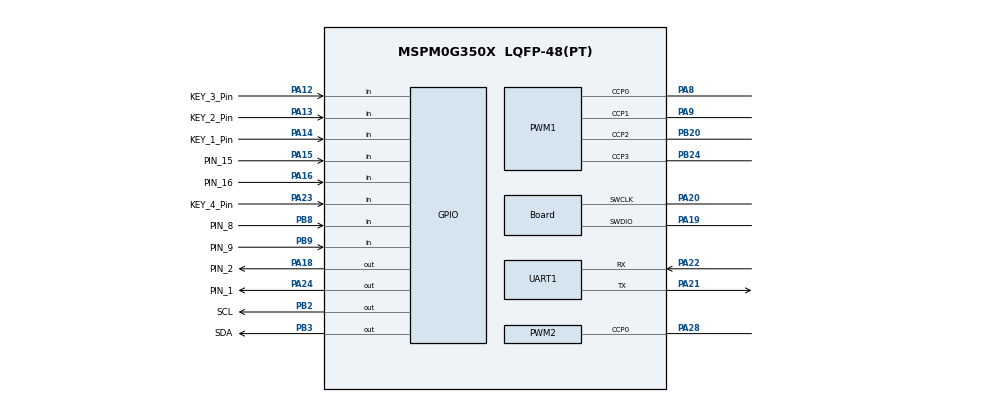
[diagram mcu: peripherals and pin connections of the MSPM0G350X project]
/**
 * @cliArgs --device "MSPM0G350X" --part "Default" --package "LQFP-48(PT)" --product "mspm0_sdk@2.04.00.06"
 * @versions {"tool":"1.22.0+3893"}
 */

/**
 * Import the modules used in this configuration.
 */
const ADC12   = scripting.addModule("/ti/driverlib/ADC12", {}, false);
const ADC121  = ADC12.addInstance();
const GPIO    = scripting.addModule("/ti/driverlib/GPIO", {}, false);
const GPIO1   = GPIO.addInstance();
const GPIO2   = GPIO.addInstance();
const GPIO3   = GPIO.addInstance();
const GPIO4   = GPIO.addInstance();
const GPIO5   = GPIO.addInstance();
const PWM     = scripting.addModule("/ti/driverlib/PWM", {}, false);
const PWM1    = PWM.addInstance();
const PWM2    = PWM.addInstance();
const SYSCTL  = scripting.addModule("/ti/driverlib/SYSCTL");
const SYSTICK = scripting.addModule("/ti/driverlib/SYSTICK");
const TIMER   = scripting.addModule("/ti/driverlib/TIMER", {}, false);
const TIMER1  = TIMER.addInstance();
const UART    = scripting.addModule("/ti/driverlib/UART", {}, false);
const UART1   = UART.addInstance();

/**
 * Write custom configuration values to the imported modules.
 */
const divider7       = system.clockTree["PLL_PDIV"];
divider7.divideValue = 8;

const divider9       = system.clockTree["UDIV"];
divider9.divideValue = 2;

const multiplier2         = system.clockTree["PLL_QDIV"];
multiplier2.multiplyValue = 40;

const mux8       = system.clockTree["HSCLKMUX"];
mux8.inputSelect = "HSCLKMUX_SYSPLL0";

ADC121.$name               = "ADC12_0";
ADC121.repeatMode          = true;
ADC121.sampClkDiv          = "DL_ADC12_CLOCK_DIVIDE_8";
ADC121.powerDownMode       = "DL_ADC12_POWER_DOWN_MODE_MANUAL";
ADC121.adcPin0Config.$name = "ti_driverlib_gpio_GPIOPinGeneric11";

const Board                       = scripting.addModule("/ti/driverlib/Board", {}, false);
Board.peripheral.$assign          = "DEBUGSS";
Board.peripheral.swclkPin.$assign = "PA20";
Board.peripheral.swdioPin.$assign = "PA19";

GPIO1.$name                               = "KEY";
GPIO1.associatedPins.create(4);
GPIO1.associatedPins[0].direction         = "INPUT";
GPIO1.associatedPins[0].internalResistor  = "PULL_UP";
GPIO1.associatedPins[0].interruptPriority = "0";
GPIO1.associatedPins[0].$name             = "KEY_1_Pin";
GPIO1.associatedPins[0].interruptEn       = true;
GPIO1.associatedPins[0].polarity          = "FALL";
GPIO1.associatedPins[0].pin.$assign       = "PA14";
GPIO1.associatedPins[1].direction         = "INPUT";
GPIO1.associatedPins[1].internalResistor  = "PULL_UP";
GPIO1.associatedPins[1].interruptPriority = "0";
GPIO1.associatedPins[1].$name             = "KEY_2_Pin";
GPIO1.associatedPins[1].interruptEn       = true;
GPIO1.associatedPins[1].polarity          = "FALL";
GPIO1.associatedPins[1].pin.$assign       = "PA13";
GPIO1.associatedPins[2].direction         = "INPUT";
GPIO1.associatedPins[2].internalResistor  = "PULL_UP";
GPIO1.associatedPins[2].interruptPriority = "0";
GPIO1.associatedPins[2].interruptEn       = true;
GPIO1.associatedPins[2].polarity          = "FALL";
GPIO1.associatedPins[2].$name             = "KEY_4_Pin";
GPIO1.associatedPins[2].pin.$assign       = "PA23";
GPIO1.associatedPins[3].direction         = "INPUT";
GPIO1.associatedPins[3].internalResistor  = "PULL_UP";
GPIO1.associatedPins[3].interruptEn       = true;
GPIO1.associatedPins[3].interruptPriority = "0";
GPIO1.associatedPins[3].polarity          = "FALL";
GPIO1.associatedPins[3].$name             = "KEY_3_Pin";
GPIO1.associatedPins[3].pin.$assign       = "PA12";

GPIO2.$name                          = "OLED";
GPIO2.associatedPins.create(2);
GPIO2.associatedPins[0].$name        = "SCL";
GPIO2.associatedPins[0].initialValue = "SET";
GPIO2.associatedPins[0].pin.$assign  = "PB2";
GPIO2.associatedPins[1].$name        = "SDA";
GPIO2.associatedPins[1].initialValue = "SET";
GPIO2.associatedPins[1].pin.$assign  = "PB3";

GPIO3.port                                = "PORTA";
GPIO3.$name                               = "GPIO_EncoderA";
GPIO3.associatedPins.create(2);
GPIO3.associatedPins[0].$name             = "PIN_15";
GPIO3.associatedPins[0].direction         = "INPUT";
GPIO3.associatedPins[0].interruptEn       = true;
GPIO3.associatedPins[0].polarity          = "RISE";
GPIO3.associatedPins[0].interruptPriority = "1";
GPIO3.associatedPins[0].pin.$assign       = "PA15";
GPIO3.associatedPins[1].$name             = "PIN_16";
GPIO3.associatedPins[1].direction         = "INPUT";
GPIO3.associatedPins[1].polarity          = "RISE";
GPIO3.associatedPins[1].interruptPriority = "1";
GPIO3.associatedPins[1].pin.$assign       = "PA16";

GPIO4.$name                               = "GPIO_EncoderB";
GPIO4.port                                = "PORTB";
GPIO4.associatedPins.create(2);
GPIO4.associatedPins[0].$name             = "PIN_8";
GPIO4.associatedPins[0].direction         = "INPUT";
GPIO4.associatedPins[0].interruptEn       = true;
GPIO4.associatedPins[0].polarity          = "RISE";
GPIO4.associatedPins[0].interruptPriority = "1";
GPIO4.associatedPins[0].pin.$assign       = "PB8";
GPIO4.associatedPins[1].$name             = "PIN_9";
GPIO4.associatedPins[1].direction         = "INPUT";
GPIO4.associatedPins[1].polarity          = "RISE";
GPIO4.associatedPins[1].interruptPriority = "1";
GPIO4.associatedPins[1].pin.$assign       = "PB9";

GPIO5.$name                         = "GPIO_GW";
GPIO5.associatedPins.create(3);
GPIO5.associatedPins[0].$name       = "PIN_0";
GPIO5.associatedPins[1].$name       = "PIN_1";
GPIO5.associatedPins[1].pin.$assign = "PA24";
GPIO5.associatedPins[2].$name       = "PIN_2";
GPIO5.associatedPins[2].pin.$assign = "PA18";

PWM1.$name                      = "PWM_0";
PWM1.clockPrescale              = 8;
PWM1.timerStartTimer            = true;
PWM1.ccIndex                    = [0,1,2,3];
PWM1.timerCount                 = 10000;
PWM1.pwmMode                    = "EDGE_ALIGN_UP";
PWM1.peripheral.$assign         = "TIMA0";
PWM1.peripheral.ccp0Pin.$assign = "PA8";
PWM1.peripheral.ccp1Pin.$assign = "PA9";
PWM1.peripheral.ccp2Pin.$assign = "PB20";
PWM1.peripheral.ccp3Pin.$assign = "PB24";
PWM1.PWM_CHANNEL_0.$name        = "ti_driverlib_pwm_PWMTimerCC0";
PWM1.PWM_CHANNEL_1.$name        = "ti_driverlib_pwm_PWMTimerCC1";
PWM1.ccp0PinConfig.$name        = "ti_driverlib_gpio_GPIOPinGeneric0";
PWM1.ccp1PinConfig.$name        = "ti_driverlib_gpio_GPIOPinGeneric1";
PWM1.PWM_CHANNEL_2.$name        = "ti_driverlib_pwm_PWMTimerCC2";
PWM1.PWM_CHANNEL_3.$name        = "ti_driverlib_pwm_PWMTimerCC3";
PWM1.ccp2PinConfig.$name        = "ti_driverlib_gpio_GPIOPinGeneric2";
PWM1.ccp3PinConfig.$name        = "ti_driverlib_gpio_GPIOPinGeneric3";

PWM2.$name                      = "PWM_1";
PWM2.timerStartTimer            = true;
PWM2.pwmMode                    = "EDGE_ALIGN_UP";
PWM2.ccIndex                    = [0];
PWM2.clockPrescale              = 80;
PWM2.timerCount                 = 20000;
PWM2.peripheral.ccp0Pin.$assign = "PA28";
PWM2.PWM_CHANNEL_0.$name        = "ti_driverlib_pwm_PWMTimerCC4";
PWM2.ccp0PinConfig.$name        = "ti_driverlib_gpio_GPIOPinGeneric10";

SYSCTL.forceDefaultClkConfig = true;
SYSCTL.clockTreeEn           = true;
SYSCTL.useHFCLK_Manual       = true;

SYSTICK.periodEnable  = true;
SYSTICK.period        = 40;
SYSTICK.systickEnable = true;

TIMER1.$name              = "TIMER_0";
TIMER1.timerMode          = "PERIODIC_UP";
TIMER1.timerPeriod        = "1 ms";
TIMER1.timerStartTimer    = true;
TIMER1.interrupts         = ["LOAD"];
TIMER1.interruptPriority  = "0";
TIMER1.timerClkPrescale   = 80;
TIMER1.peripheral.$assign = "TIMA1";

UART1.$name                                = "MAIX";
UART1.enableFIFO                           = true;
UART1.rxFifoThreshold                      = "DL_UART_RX_FIFO_LEVEL_ONE_ENTRY";
UART1.txFifoThreshold                      = "DL_UART_TX_FIFO_LEVEL_ONE_ENTRY";
UART1.interruptPriority                    = "0";
UART1.enabledDMARXTriggers                 = "DL_UART_DMA_INTERRUPT_RX";
UART1.enabledInterrupts                    = ["DMA_DONE_RX"];
UART1.targetBaudRate                       = 115200;
UART1.peripheral.$assign                   = "UART2";
UART1.peripheral.rxPin.$assign             = "PA22";
UART1.peripheral.txPin.$assign             = "PA21";
UART1.txPinConfig.direction                = scripting.forceWrite("OUTPUT");
UART1.txPinConfig.hideOutputInversion      = scripting.forceWrite(false);
UART1.txPinConfig.onlyInternalResistor     = scripting.forceWrite(false);
UART1.txPinConfig.passedPeripheralType     = scripting.forceWrite("Digital");
UART1.txPinConfig.$name                    = "ti_driverlib_gpio_GPIOPinGeneric4";
UART1.rxPinConfig.hideOutputInversion      = scripting.forceWrite(false);
UART1.rxPinConfig.onlyInternalResistor     = scripting.forceWrite(false);
UART1.rxPinConfig.passedPeripheralType     = scripting.forceWrite("Digital");
UART1.rxPinConfig.$name                    = "ti_driverlib_gpio_GPIOPinGeneric5";
UART1.DMA_CHANNEL_RX.$name                 = "DMA_CH1";
UART1.DMA_CHANNEL_RX.addressMode           = "f2b";
UART1.DMA_CHANNEL_RX.srcLength             = "BYTE";
UART1.DMA_CHANNEL_RX.dstLength             = "BYTE";
UART1.DMA_CHANNEL_RX.configureTransferSize = true;
UART1.DMA_CHANNEL_RX.transferMode          = "FULL_CH_REPEAT_SINGLE";

const ProjectConfig              = scripting.addModule("/ti/project_config/ProjectConfig", {}, false);
ProjectConfig.migrationCondition = true;

/**
 * Pinmux solution for unlocked pins/peripherals. This ensures that minor changes to the automatic solver in a future
 * version of the tool will not impact the pinmux you originally saw.  These lines can be completely deleted in order to
 * re-solve from scratch.
 */
ADC121.peripheral.$suggestSolution               = "ADC0";
ADC121.peripheral.adcPin0.$suggestSolution       = "PA27";
GPIO5.associatedPins[0].pin.$suggestSolution     = "PA0";
PWM2.peripheral.$suggestSolution                 = "TIMG7";
UART1.DMA_CHANNEL_RX.peripheral.$suggestSolution = "DMA_CH0";
